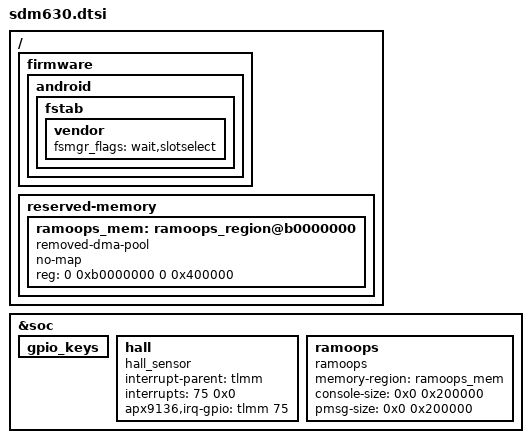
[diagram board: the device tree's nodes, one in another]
/* Copyright (c) 2016-2018, The Linux Foundation. All rights reserved.
 *
 * This program is free software; you can redistribute it and/or modify
 * it under the terms of the GNU General Public License version 2 and
 * only version 2 as published by the Free Software Foundation.
 *
 * This program is distributed in the hope that it will be useful,
 * but WITHOUT ANY WARRANTY; without even the implied warranty of
 * MERCHANTABILITY or FITNESS FOR A PARTICULAR PURPOSE.  See the
 * GNU General Public License for more details.
 */

/ {
	firmware: firmware {
		android {
			fstab {
				vendor {
					fsmgr_flags = "wait,slotselect";
				};
			};
		};
	};


};


&soc {
	gpio_keys {
		/delete-node/ camera_focus;
		/delete-node/ camera_snapshot;
	};

	hall {
		compatible = "hall_sensor";
		interrupt-parent = <&tlmm>;
		interrupts = <75 0x0>;
		apx9136,irq-gpio = <&tlmm 75 0x2008>;
	};

};


// custom
/ {
	reserved-memory {
		ramoops_mem: ramoops_region@b0000000 {
			compatible = "removed-dma-pool";
			no-map;
			reg = <0 0xb0000000 0 0x400000>;
		};
	};
};

&soc {
	ramoops {
		compatible = "ramoops";
		memory-region = <&ramoops_mem>;
		console-size = <0x0 0x200000>;
		pmsg-size = <0x0 0x200000>;
	};
};
